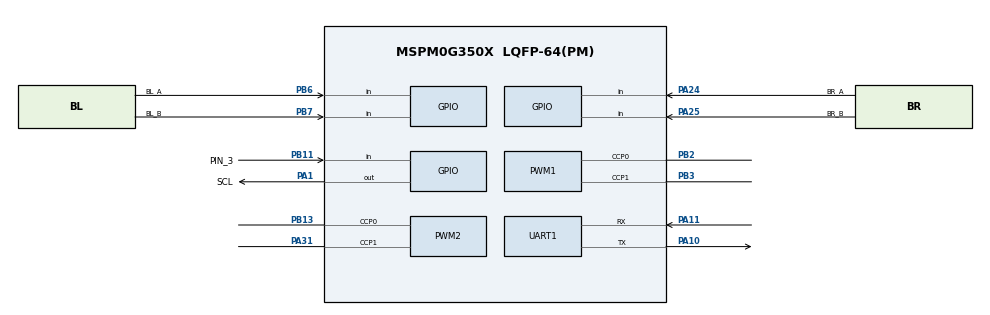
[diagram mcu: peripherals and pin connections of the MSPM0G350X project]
/**
 * @cliArgs --device "MSPM0G350X" --part "Default" --package "LQFP-64(PM)" --product "mspm0_sdk@2.05.01.00"
 * @versions {"tool":"1.24.0+4110"}
 */

/**
 * Import the modules used in this configuration.
 */
const GPIO   = scripting.addModule("/ti/driverlib/GPIO", {}, false);
const GPIO1  = GPIO.addInstance();
const GPIO2  = GPIO.addInstance();
const GPIO3  = GPIO.addInstance();
const GPIO4  = GPIO.addInstance();
const GPIO5  = GPIO.addInstance();
const PWM    = scripting.addModule("/ti/driverlib/PWM", {}, false);
const PWM1   = PWM.addInstance();
const PWM2   = PWM.addInstance();
const SYSCTL = scripting.addModule("/ti/driverlib/SYSCTL");
const TIMER  = scripting.addModule("/ti/driverlib/TIMER", {}, false);
const TIMER1 = TIMER.addInstance();
const TIMER2 = TIMER.addInstance();
const UART   = scripting.addModule("/ti/driverlib/UART", {}, false);
const UART1  = UART.addInstance();

/**
 * Write custom configuration values to the imported modules.
 */
const divider6       = system.clockTree["PLL_CLK2X_DIV"];
divider6.divideValue = 4;

const divider7       = system.clockTree["PLL_PDIV"];
divider7.divideValue = 2;

const divider9       = system.clockTree["UDIV"];
divider9.divideValue = 2;

const multiplier2         = system.clockTree["PLL_QDIV"];
multiplier2.multiplyValue = 10;

const mux8       = system.clockTree["HSCLKMUX"];
mux8.inputSelect = "HSCLKMUX_SYSPLL2X";

GPIO1.$name                              = "MOTOR";
GPIO1.associatedPins.create(8);
GPIO1.associatedPins[0].assignedPort     = "PORTB";
GPIO1.associatedPins[0].internalResistor = "PULL_UP";
GPIO1.associatedPins[0].$name            = "BL_IN1";
GPIO1.associatedPins[0].assignedPin      = "1";
GPIO1.associatedPins[1].assignedPort     = "PORTB";
GPIO1.associatedPins[1].internalResistor = "PULL_UP";
GPIO1.associatedPins[1].$name            = "BL_IN2";
GPIO1.associatedPins[1].assignedPin      = "0";
GPIO1.associatedPins[2].internalResistor = "PULL_UP";
GPIO1.associatedPins[2].$name            = "FL_IN1";
GPIO1.associatedPins[2].assignedPort     = "PORTA";
GPIO1.associatedPins[2].assignedPin      = "28";
GPIO1.associatedPins[3].internalResistor = "PULL_UP";
GPIO1.associatedPins[3].assignedPort     = "PORTB";
GPIO1.associatedPins[3].assignedPin      = "4";
GPIO1.associatedPins[3].$name            = "FL_IN2";
GPIO1.associatedPins[4].$name            = "FR_IN1";
GPIO1.associatedPins[4].internalResistor = "PULL_UP";
GPIO1.associatedPins[4].assignedPort     = "PORTB";
GPIO1.associatedPins[4].assignedPin      = "19";
GPIO1.associatedPins[5].$name            = "FR_IN2";
GPIO1.associatedPins[5].internalResistor = "PULL_UP";
GPIO1.associatedPins[5].assignedPin      = "18";
GPIO1.associatedPins[5].assignedPort     = "PORTB";
GPIO1.associatedPins[6].$name            = "BR_IN1";
GPIO1.associatedPins[6].internalResistor = "PULL_UP";
GPIO1.associatedPins[6].assignedPort     = "PORTA";
GPIO1.associatedPins[6].assignedPin      = "15";
GPIO1.associatedPins[7].$name            = "BR_IN2";
GPIO1.associatedPins[7].assignedPort     = "PORTA";
GPIO1.associatedPins[7].internalResistor = "PULL_UP";
GPIO1.associatedPins[7].assignedPin      = "17";

const Board = scripting.addModule("/ti/driverlib/Board", {}, false);

GPIO2.$name                               = "ENCODER";
GPIO2.associatedPins.create(8);
GPIO2.associatedPins[0].$name             = "BL_A";
GPIO2.associatedPins[0].direction         = "INPUT";
GPIO2.associatedPins[0].assignedPort      = "PORTB";
GPIO2.associatedPins[0].assignedPin       = "6";
GPIO2.associatedPins[0].interruptEn       = true;
GPIO2.associatedPins[0].polarity          = "RISE";
GPIO2.associatedPins[0].internalResistor  = "PULL_UP";
GPIO2.associatedPins[0].interruptPriority = "1";
GPIO2.associatedPins[0].pin.$assign       = "PB6";
GPIO2.associatedPins[1].$name             = "BL_B";
GPIO2.associatedPins[1].direction         = "INPUT";
GPIO2.associatedPins[1].internalResistor  = "PULL_UP";
GPIO2.associatedPins[1].assignedPort      = "PORTB";
GPIO2.associatedPins[1].assignedPin       = "7";
GPIO2.associatedPins[1].polarity          = "RISE";
GPIO2.associatedPins[1].interruptPriority = "0";
GPIO2.associatedPins[1].pin.$assign       = "PB7";
GPIO2.associatedPins[2].$name             = "BR_A";
GPIO2.associatedPins[2].direction         = "INPUT";
GPIO2.associatedPins[2].internalResistor  = "PULL_UP";
GPIO2.associatedPins[2].assignedPort      = "PORTA";
GPIO2.associatedPins[2].assignedPin       = "24";
GPIO2.associatedPins[2].interruptEn       = true;
GPIO2.associatedPins[2].polarity          = "RISE";
GPIO2.associatedPins[2].interruptPriority = "1";
GPIO2.associatedPins[2].pin.$assign       = "PA24";
GPIO2.associatedPins[3].$name             = "BR_B";
GPIO2.associatedPins[3].direction         = "INPUT";
GPIO2.associatedPins[3].internalResistor  = "PULL_UP";
GPIO2.associatedPins[3].assignedPort      = "PORTA";
GPIO2.associatedPins[3].assignedPin       = "25";
GPIO2.associatedPins[3].pin.$assign       = "PA25";
GPIO2.associatedPins[4].$name             = "FL_A";
GPIO2.associatedPins[4].assignedPort      = "PORTB";
GPIO2.associatedPins[4].assignedPin       = "15";
GPIO2.associatedPins[4].direction         = "INPUT";
GPIO2.associatedPins[4].polarity          = "RISE";
GPIO2.associatedPins[4].interruptPriority = "1";
GPIO2.associatedPins[5].$name             = "FL_B";
GPIO2.associatedPins[5].direction         = "INPUT";
GPIO2.associatedPins[5].assignedPort      = "PORTB";
GPIO2.associatedPins[5].assignedPin       = "16";
GPIO2.associatedPins[6].$name             = "FR_A";
GPIO2.associatedPins[6].direction         = "INPUT";
GPIO2.associatedPins[6].assignedPort      = "PORTA";
GPIO2.associatedPins[6].assignedPin       = "26";
GPIO2.associatedPins[6].polarity          = "RISE";
GPIO2.associatedPins[6].interruptPriority = "1";
GPIO2.associatedPins[7].$name             = "FR_B";
GPIO2.associatedPins[7].direction         = "INPUT";
GPIO2.associatedPins[7].assignedPort      = "PORTA";
GPIO2.associatedPins[7].assignedPin       = "27";

GPIO3.$name                          = "OLED";
GPIO3.associatedPins.create(2);
GPIO3.associatedPins[0].initialValue = "SET";
GPIO3.associatedPins[0].assignedPort = "PORTA";
GPIO3.associatedPins[0].assignedPin  = "0";
GPIO3.associatedPins[0].$name        = "SDA";
GPIO3.associatedPins[1].$name        = "SCL";
GPIO3.associatedPins[1].initialValue = "SET";
GPIO3.associatedPins[1].assignedPort = "PORTA";
GPIO3.associatedPins[1].assignedPin  = "1";
GPIO3.associatedPins[1].pin.$assign  = "PA1";

GPIO4.$name                          = "GRAYSCALE";
GPIO4.associatedPins.create(8);
GPIO4.associatedPins[0].$name        = "PIN_0";
GPIO4.associatedPins[0].direction    = "INPUT";
GPIO4.associatedPins[0].assignedPort = "PORTB";
GPIO4.associatedPins[0].assignedPin  = "27";
GPIO4.associatedPins[1].$name        = "PIN_1";
GPIO4.associatedPins[1].direction    = "INPUT";
GPIO4.associatedPins[1].assignedPort = "PORTB";
GPIO4.associatedPins[1].assignedPin  = "26";
GPIO4.associatedPins[2].$name        = "PIN_2";
GPIO4.associatedPins[2].direction    = "INPUT";
GPIO4.associatedPins[2].assignedPort = "PORTB";
GPIO4.associatedPins[2].assignedPin  = "22";
GPIO4.associatedPins[3].$name        = "PIN_3";
GPIO4.associatedPins[3].direction    = "INPUT";
GPIO4.associatedPins[3].assignedPort = "PORTB";
GPIO4.associatedPins[3].assignedPin  = "11";
GPIO4.associatedPins[3].pin.$assign  = "PB11";
GPIO4.associatedPins[4].$name        = "PIN_4";
GPIO4.associatedPins[4].direction    = "INPUT";
GPIO4.associatedPins[4].assignedPort = "PORTB";
GPIO4.associatedPins[4].assignedPin  = "5";
GPIO4.associatedPins[5].$name        = "PIN_5";
GPIO4.associatedPins[5].direction    = "INPUT";
GPIO4.associatedPins[5].assignedPort = "PORTB";
GPIO4.associatedPins[5].assignedPin  = "10";
GPIO4.associatedPins[6].$name        = "PIN_6";
GPIO4.associatedPins[6].direction    = "INPUT";
GPIO4.associatedPins[6].assignedPort = "PORTA";
GPIO4.associatedPins[6].assignedPin  = "14";
GPIO4.associatedPins[7].$name        = "PIN_7";
GPIO4.associatedPins[7].direction    = "INPUT";
GPIO4.associatedPins[7].assignedPort = "PORTA";
GPIO4.associatedPins[7].assignedPin  = "7";

GPIO5.$name                              = "BUTTON";
GPIO5.associatedPins[0].$name            = "SW2";
GPIO5.associatedPins[0].internalResistor = "PULL_UP";
GPIO5.associatedPins[0].direction        = "INPUT";
GPIO5.associatedPins[0].assignedPort     = "PORTB";
GPIO5.associatedPins[0].assignedPin      = "21";

PWM1.$name                              = "PWM_G6";
PWM1.retentionRestoreCnt                = true;
PWM1.overrideRetention                  = true;
PWM1.pwmMode                            = "EDGE_ALIGN_UP";
PWM1.timerCount                         = 10000;
PWM1.peripheral.$assign                 = "TIMG6";
PWM1.peripheral.ccp0Pin.$assign         = "PB2";
PWM1.peripheral.ccp1Pin.$assign         = "PB3";
PWM1.PWM_CHANNEL_0.$name                = "ti_driverlib_pwm_PWMTimerCC2";
PWM1.PWM_CHANNEL_1.$name                = "ti_driverlib_pwm_PWMTimerCC3";
PWM1.ccp0PinConfig.direction            = scripting.forceWrite("OUTPUT");
PWM1.ccp0PinConfig.hideOutputInversion  = scripting.forceWrite(false);
PWM1.ccp0PinConfig.onlyInternalResistor = scripting.forceWrite(false);
PWM1.ccp0PinConfig.passedPeripheralType = scripting.forceWrite("Digital");
PWM1.ccp0PinConfig.$name                = "ti_driverlib_gpio_GPIOPinGeneric2";
PWM1.ccp1PinConfig.direction            = scripting.forceWrite("OUTPUT");
PWM1.ccp1PinConfig.hideOutputInversion  = scripting.forceWrite(false);
PWM1.ccp1PinConfig.onlyInternalResistor = scripting.forceWrite(false);
PWM1.ccp1PinConfig.passedPeripheralType = scripting.forceWrite("Digital");
PWM1.ccp1PinConfig.$name                = "ti_driverlib_gpio_GPIOPinGeneric3";

PWM2.$name                              = "PWM_G12";
PWM2.pwmMode                            = "EDGE_ALIGN_UP";
PWM2.timerCount                         = 10000;
PWM2.peripheral.$assign                 = "TIMG12";
PWM2.peripheral.ccp0Pin.$assign         = "PB13";
PWM2.peripheral.ccp1Pin.$assign         = "PA31";
PWM2.PWM_CHANNEL_0.$name                = "ti_driverlib_pwm_PWMTimerCC4";
PWM2.PWM_CHANNEL_1.$name                = "ti_driverlib_pwm_PWMTimerCC5";
PWM2.ccp0PinConfig.direction            = scripting.forceWrite("OUTPUT");
PWM2.ccp0PinConfig.hideOutputInversion  = scripting.forceWrite(false);
PWM2.ccp0PinConfig.onlyInternalResistor = scripting.forceWrite(false);
PWM2.ccp0PinConfig.passedPeripheralType = scripting.forceWrite("Digital");
PWM2.ccp0PinConfig.$name                = "ti_driverlib_gpio_GPIOPinGeneric4";
PWM2.ccp1PinConfig.direction            = scripting.forceWrite("OUTPUT");
PWM2.ccp1PinConfig.hideOutputInversion  = scripting.forceWrite(false);
PWM2.ccp1PinConfig.onlyInternalResistor = scripting.forceWrite(false);
PWM2.ccp1PinConfig.passedPeripheralType = scripting.forceWrite("Digital");
PWM2.ccp1PinConfig.$name                = "ti_driverlib_gpio_GPIOPinGeneric5";

SYSCTL.forceDefaultClkConfig = true;
SYSCTL.clockTreeEn           = true;
scripting.suppress("For best practices when the CPUCLK is running at 32MHz and above, clear the flash status bit using DL_FlashCTL_executeClearStatus\\(\\) before executing any flash operation\\. Otherwise there may be false positives\\.", SYSCTL);

TIMER1.timerClkPrescale   = 256;
TIMER1.timerPeriod        = "10 ms";
TIMER1.interrupts         = ["ZERO"];
TIMER1.timerMode          = "PERIODIC";
TIMER1.interruptPriority  = "1";
TIMER1.$name              = "TIMER_G0";
TIMER1.peripheral.$assign = "TIMG0";

TIMER2.$name              = "TIMER_G7";
TIMER2.timerClkPrescale   = 256;
TIMER2.interrupts         = ["ZERO"];
TIMER2.interruptPriority  = "2";
TIMER2.timerMode          = "PERIODIC_UP";
TIMER2.timerPeriod        = "20 ms";
TIMER2.peripheral.$assign = "TIMG7";

UART1.$name                    = "UART_0";
UART1.peripheral.$assign       = "UART0";
UART1.peripheral.rxPin.$assign = "PA11";
UART1.peripheral.txPin.$assign = "PA10";
UART1.txPinConfig.$name        = "ti_driverlib_gpio_GPIOPinGeneric0";
UART1.rxPinConfig.$name        = "ti_driverlib_gpio_GPIOPinGeneric1";

/**
 * Pinmux solution for unlocked pins/peripherals. This ensures that minor changes to the automatic solver in a future
 * version of the tool will not impact the pinmux you originally saw.  These lines can be completely deleted in order to
 * re-solve from scratch.
 */
GPIO1.associatedPins[0].pin.$suggestSolution = "PB1";
GPIO1.associatedPins[1].pin.$suggestSolution = "PB0";
GPIO1.associatedPins[2].pin.$suggestSolution = "PA28";
GPIO1.associatedPins[3].pin.$suggestSolution = "PB4";
GPIO1.associatedPins[4].pin.$suggestSolution = "PB19";
GPIO1.associatedPins[5].pin.$suggestSolution = "PB18";
GPIO1.associatedPins[6].pin.$suggestSolution = "PA15";
GPIO1.associatedPins[7].pin.$suggestSolution = "PA17";
Board.peripheral.$suggestSolution            = "DEBUGSS";
Board.peripheral.swclkPin.$suggestSolution   = "PA20";
Board.peripheral.swdioPin.$suggestSolution   = "PA19";
GPIO2.associatedPins[4].pin.$suggestSolution = "PB15";
GPIO2.associatedPins[5].pin.$suggestSolution = "PB16";
GPIO2.associatedPins[6].pin.$suggestSolution = "PA26";
GPIO2.associatedPins[7].pin.$suggestSolution = "PA27";
GPIO3.associatedPins[0].pin.$suggestSolution = "PA0";
GPIO4.associatedPins[0].pin.$suggestSolution = "PB27";
GPIO4.associatedPins[1].pin.$suggestSolution = "PB26";
GPIO4.associatedPins[2].pin.$suggestSolution = "PB22";
GPIO4.associatedPins[4].pin.$suggestSolution = "PB5";
GPIO4.associatedPins[5].pin.$suggestSolution = "PB10";
GPIO4.associatedPins[6].pin.$suggestSolution = "PA14";
GPIO4.associatedPins[7].pin.$suggestSolution = "PA7";
GPIO5.associatedPins[0].pin.$suggestSolution = "PB21";
